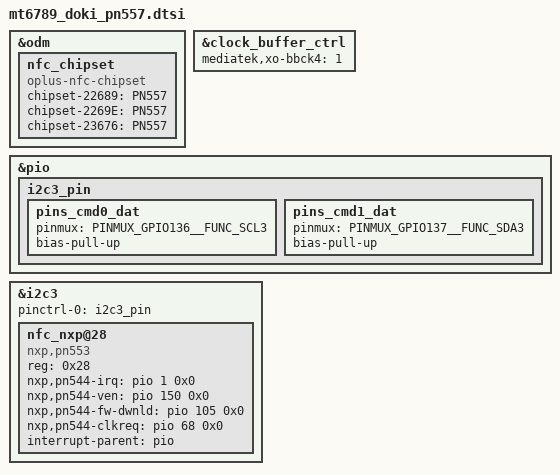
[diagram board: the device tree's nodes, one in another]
/**********************************************************************************
* Copyright (c)  2008-2020  Guangdong oplus Mobile Comm Corp., Ltd
*
***********************************************************************************/
&odm {
	nfc_chipset:nfc_chipset {
		compatible = "oplus-nfc-chipset";
		chipset-22689 = "PN557";
		chipset-2269E = "PN557";
		chipset-23676 = "PN557";
	};
};

&clock_buffer_ctrl {
	mediatek,xo-bbck4 = <1>;
};


&pio {
        i2c3_pin: i2c3_pin {
                pins_cmd0_dat {
                        pinmux = <PINMUX_GPIO136__FUNC_SCL3>;
                        bias-pull-up;
                };

                pins_cmd1_dat {
                        pinmux = <PINMUX_GPIO137__FUNC_SDA3>;
                        bias-pull-up;
                };
        };
};

&i2c3 {
       status = "okay";
       pinctrl-0 = <&i2c3_pin>;
       nfc_nxp@28 {
               compatible = "nxp,pn553";
               reg = <0x28>;
               nxp,pn544-irq = <&pio 1 0x0>;
               nxp,pn544-ven = <&pio 150 0x0>;
               nxp,pn544-fw-dwnld = <&pio 105 0x0>;
               nxp,pn544-clkreq = <&pio 68 0x0>;
               interrupt-parent = <&pio>;
       };
};
